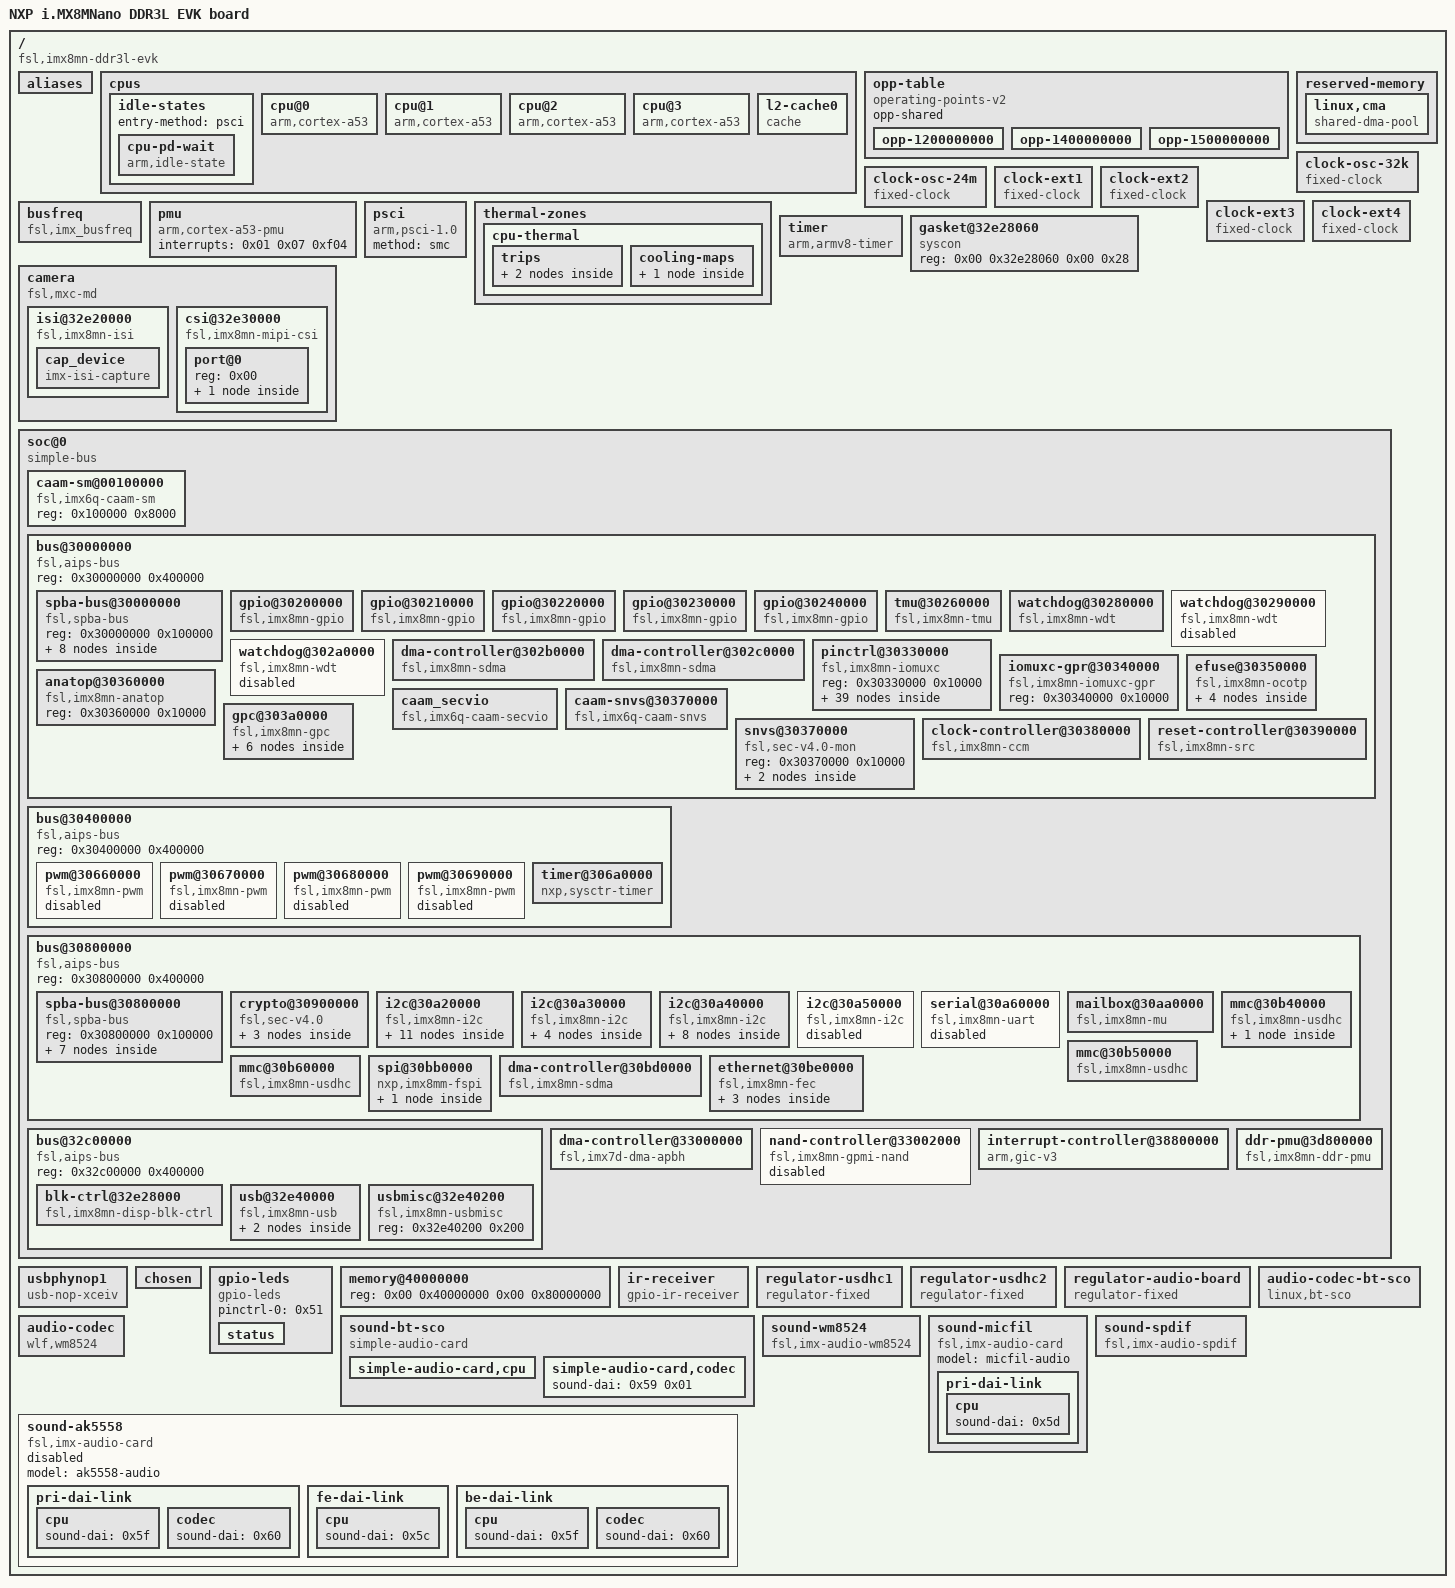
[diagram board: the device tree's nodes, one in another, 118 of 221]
/dts-v1/;

/ {
	interrupt-parent = <0x01>;
	#address-cells = <0x02>;
	#size-cells = <0x02>;
	model = "NXP i.MX8MNano DDR3L EVK board";
	compatible = "fsl,imx8mn-ddr3l-evk\0fsl,imx8mn";

	aliases {
		ethernet0 = "/soc@0/bus@30800000/ethernet@30be0000";
		gpio0 = "/soc@0/bus@30000000/gpio@30200000";
		gpio1 = "/soc@0/bus@30000000/gpio@30210000";
		gpio2 = "/soc@0/bus@30000000/gpio@30220000";
		gpio3 = "/soc@0/bus@30000000/gpio@30230000";
		gpio4 = "/soc@0/bus@30000000/gpio@30240000";
		i2c0 = "/soc@0/bus@30800000/i2c@30a20000";
		i2c1 = "/soc@0/bus@30800000/i2c@30a30000";
		i2c2 = "/soc@0/bus@30800000/i2c@30a40000";
		i2c3 = "/soc@0/bus@30800000/i2c@30a50000";
		mmc0 = "/soc@0/bus@30800000/mmc@30b40000";
		mmc1 = "/soc@0/bus@30800000/mmc@30b50000";
		mmc2 = "/soc@0/bus@30800000/mmc@30b60000";
		serial0 = "/soc@0/bus@30800000/spba-bus@30800000/serial@30860000";
		serial1 = "/soc@0/bus@30800000/spba-bus@30800000/serial@30890000";
		serial2 = "/soc@0/bus@30800000/spba-bus@30800000/serial@30880000";
		serial3 = "/soc@0/bus@30800000/serial@30a60000";
		spi0 = "/soc@0/bus@30800000/spba-bus@30800000/spi@30820000";
		spi1 = "/soc@0/bus@30800000/spba-bus@30800000/spi@30830000";
		spi2 = "/soc@0/bus@30800000/spba-bus@30800000/spi@30840000";
		isi0 = "/camera/isi@32e20000";
		csi0 = "/camera/csi@32e30000";
	};

	cpus {
		#address-cells = <0x01>;
		#size-cells = <0x00>;

		idle-states {
			entry-method = "psci";

			cpu-pd-wait {
				compatible = "arm,idle-state";
				arm,psci-suspend-param = <0x10033>;
				local-timer-stop;
				entry-latency-us = <0x3e8>;
				exit-latency-us = <0x2bc>;
				min-residency-us = <0xa8c>;
				phandle = <0x06>;
			};
		};

		cpu@0 {
			device_type = "cpu";
			compatible = "arm,cortex-a53";
			reg = <0x00>;
			clock-latency = <0xee6c>;
			clocks = <0x02 0xbf>;
			enable-method = "psci";
			i-cache-size = <0x8000>;
			i-cache-line-size = <0x40>;
			i-cache-sets = <0x100>;
			d-cache-size = <0x8000>;
			d-cache-line-size = <0x40>;
			d-cache-sets = <0x80>;
			next-level-cache = <0x03>;
			operating-points-v2 = <0x04>;
			nvmem-cells = <0x05>;
			nvmem-cell-names = "speed_grade";
			cpu-idle-states = <0x06>;
			#cooling-cells = <0x02>;
			cpu-supply = <0x07>;
			phandle = <0x0a>;
		};

		cpu@1 {
			device_type = "cpu";
			compatible = "arm,cortex-a53";
			reg = <0x01>;
			clock-latency = <0xee6c>;
			clocks = <0x02 0xbf>;
			enable-method = "psci";
			i-cache-size = <0x8000>;
			i-cache-line-size = <0x40>;
			i-cache-sets = <0x100>;
			d-cache-size = <0x8000>;
			d-cache-line-size = <0x40>;
			d-cache-sets = <0x80>;
			next-level-cache = <0x03>;
			operating-points-v2 = <0x04>;
			cpu-idle-states = <0x06>;
			#cooling-cells = <0x02>;
			cpu-supply = <0x07>;
			phandle = <0x0b>;
		};

		cpu@2 {
			device_type = "cpu";
			compatible = "arm,cortex-a53";
			reg = <0x02>;
			clock-latency = <0xee6c>;
			clocks = <0x02 0xbf>;
			enable-method = "psci";
			i-cache-size = <0x8000>;
			i-cache-line-size = <0x40>;
			i-cache-sets = <0x100>;
			d-cache-size = <0x8000>;
			d-cache-line-size = <0x40>;
			d-cache-sets = <0x80>;
			next-level-cache = <0x03>;
			operating-points-v2 = <0x04>;
			cpu-idle-states = <0x06>;
			#cooling-cells = <0x02>;
			cpu-supply = <0x07>;
			phandle = <0x0c>;
		};

		cpu@3 {
			device_type = "cpu";
			compatible = "arm,cortex-a53";
			reg = <0x03>;
			clock-latency = <0xee6c>;
			clocks = <0x02 0xbf>;
			enable-method = "psci";
			i-cache-size = <0x8000>;
			i-cache-line-size = <0x40>;
			i-cache-sets = <0x100>;
			d-cache-size = <0x8000>;
			d-cache-line-size = <0x40>;
			d-cache-sets = <0x80>;
			next-level-cache = <0x03>;
			operating-points-v2 = <0x04>;
			cpu-idle-states = <0x06>;
			#cooling-cells = <0x02>;
			cpu-supply = <0x07>;
			phandle = <0x0d>;
		};

		l2-cache0 {
			compatible = "cache";
			cache-level = <0x02>;
			cache-size = <0x80000>;
			cache-line-size = <0x40>;
			cache-sets = <0x200>;
			phandle = <0x03>;
		};
	};

	opp-table {
		compatible = "operating-points-v2";
		opp-shared;
		phandle = <0x04>;

		opp-1200000000 {
			opp-hz = <0x00 0x47868c00>;
			opp-microvolt = <0xcf850>;
			opp-supported-hw = <0xb00 0x07>;
			clock-latency-ns = <0x249f0>;
			opp-suspend;
		};

		opp-1400000000 {
			opp-hz = <0x00 0x53724e00>;
			opp-microvolt = <0xe7ef0>;
			opp-supported-hw = <0x300 0x07>;
			clock-latency-ns = <0x249f0>;
			opp-suspend;
		};

		opp-1500000000 {
			opp-hz = <0x00 0x59682f00>;
			opp-microvolt = <0xf4240>;
			opp-supported-hw = <0x100 0x03>;
			clock-latency-ns = <0x249f0>;
			opp-suspend;
		};
	};

	reserved-memory {
		#address-cells = <0x02>;
		#size-cells = <0x02>;
		ranges;

		linux,cma {
			compatible = "shared-dma-pool";
			reusable;
			size = <0x00 0x28000000>;
			alloc-ranges = <0x00 0x40000000 0x00 0x40000000>;
			linux,cma-default;
		};
	};

	clock-osc-32k {
		compatible = "fixed-clock";
		#clock-cells = <0x00>;
		clock-frequency = <0x8000>;
		clock-output-names = "osc_32k";
		phandle = <0x1b>;
	};

	clock-osc-24m {
		compatible = "fixed-clock";
		#clock-cells = <0x00>;
		clock-frequency = <0x16e3600>;
		clock-output-names = "osc_24m";
		phandle = <0x1c>;
	};

	clock-ext1 {
		compatible = "fixed-clock";
		#clock-cells = <0x00>;
		clock-frequency = <0x7ed6b40>;
		clock-output-names = "clk_ext1";
		phandle = <0x1d>;
	};

	clock-ext2 {
		compatible = "fixed-clock";
		#clock-cells = <0x00>;
		clock-frequency = <0x7ed6b40>;
		clock-output-names = "clk_ext2";
		phandle = <0x1e>;
	};

	clock-ext3 {
		compatible = "fixed-clock";
		#clock-cells = <0x00>;
		clock-frequency = <0x7ed6b40>;
		clock-output-names = "clk_ext3";
		phandle = <0x1f>;
	};

	clock-ext4 {
		compatible = "fixed-clock";
		#clock-cells = <0x00>;
		clock-frequency = <0x7ed6b40>;
		clock-output-names = "clk_ext4";
		phandle = <0x20>;
	};

	busfreq {
		compatible = "fsl,imx_busfreq";
		clocks = <0x02 0x29 0x02 0x59 0x02 0x5a 0x02 0x5a 0x02 0x58 0x02 0x5b 0x02 0x30 0x02 0x32 0x02 0x3f 0x02 0x53 0x02 0x54 0x02 0x4b 0x02 0x02 0x02 0x38 0x02 0x15>;
		clock-names = "dram_pll\0dram_alt_src\0dram_apb_src\0dram_apb_pre_div\0dram_core\0dram_alt_root\0sys_pll1_40m\0sys_pll1_100m\0sys_pll2_333m\0noc_div\0ahb_div\0main_axi_src\0osc_24m\0sys_pll1_800m\0dram_pll_div";
	};

	pmu {
		compatible = "arm,cortex-a53-pmu";
		interrupts = <0x01 0x07 0xf04>;
	};

	psci {
		compatible = "arm,psci-1.0";
		method = "smc";
	};

	thermal-zones {

		cpu-thermal {
			polling-delay-passive = <0xfa>;
			polling-delay = <0x7d0>;
			thermal-sensors = <0x08>;

			trips {

				trip0 {
					temperature = <0x14c08>;
					hysteresis = <0x7d0>;
					type = "passive";
					phandle = <0x09>;
				};

				trip1 {
					temperature = <0x17318>;
					hysteresis = <0x7d0>;
					type = "critical";
				};
			};

			cooling-maps {

				map0 {
					trip = <0x09>;
					cooling-device = <0x0a 0xffffffff 0xffffffff 0x0b 0xffffffff 0xffffffff 0x0c 0xffffffff 0xffffffff 0x0d 0xffffffff 0xffffffff>;
				};
			};
		};
	};

	timer {
		compatible = "arm,armv8-timer";
		interrupts = <0x01 0x0d 0xf08 0x01 0x0e 0xf08 0x01 0x0b 0xf08 0x01 0x0a 0xf08>;
		clock-frequency = <0x7a1200>;
		arm,no-tick-in-suspend;
	};

	gasket@32e28060 {
		compatible = "syscon";
		reg = <0x00 0x32e28060 0x00 0x28>;
		phandle = <0x0f>;
	};

	camera {
		compatible = "fsl,mxc-md\0simple-bus";
		#address-cells = <0x02>;
		#size-cells = <0x02>;
		ranges;
		status = "okay";

		isi@32e20000 {
			compatible = "fsl,imx8mn-isi";
			reg = <0x00 0x32e20000 0x00 0x2000>;
			power-domains = <0x0e 0x03>;
			interrupts = <0x00 0x10 0x04>;
			interface = <0x02 0x00 0x02>;
			clocks = <0x02 0x4e 0x02 0x4f 0x02 0xb8 0x02 0xb9>;
			clock-names = "disp_axi\0disp_apb\0disp_axi_root\0disp_apb_root";
			assigned-clocks = <0x02 0xb8 0x02 0xb9>;
			assigned-clock-rates = <0x1dcd6500 0xbebc200>;
			no-reset-control;
			status = "okay";

			cap_device {
				compatible = "imx-isi-capture";
				status = "okay";
			};
		};

		csi@32e30000 {
			compatible = "fsl,imx8mn-mipi-csi";
			reg = <0x00 0x32e30000 0x00 0x10000>;
			interrupts = <0x00 0x11 0x04>;
			clock-frequency = <0x13d92d40>;
			clocks = <0x02 0x81 0x02 0xb8 0x02 0xb9>;
			clock-names = "mipi_clk\0disp_axi\0disp_apb";
			assigned-clocks = <0x02 0x81>;
			assigned-clock-parents = <0x02 0x41>;
			assigned-clock-rates = <0x13d92d40>;
			bus-width = <0x04>;
			csi-gpr = <0x0f>;
			power-domains = <0x0e 0x01>;
			status = "okay";
			#address-cells = <0x01>;
			#size-cells = <0x00>;

			port@0 {
				reg = <0x00>;

				endpoint {
					remote-endpoint = <0x10>;
					data-lanes = <0x02>;
					csis-hs-settle = <0x0d>;
					csis-clk-settle = <0x02>;
					csis-wclk;
					phandle = <0x35>;
				};
			};
		};
	};

	soc@0 {
		compatible = "simple-bus";
		#address-cells = <0x01>;
		#size-cells = <0x01>;
		ranges = <0x00 0x00 0x00 0x3e000000>;
		dma-ranges = <0x40000000 0x00 0x40000000 0xc0000000>;
		nvmem-cells = <0x11>;
		nvmem-cell-names = "soc_unique_id";

		caam-sm@00100000 {
			compatible = "fsl,imx6q-caam-sm";
			reg = <0x100000 0x8000>;
		};

		bus@30000000 {
			compatible = "fsl,aips-bus\0simple-bus";
			reg = <0x30000000 0x400000>;
			#address-cells = <0x01>;
			#size-cells = <0x01>;
			ranges;

			spba-bus@30000000 {
				compatible = "fsl,spba-bus\0simple-bus";
				#address-cells = <0x01>;
				#size-cells = <0x01>;
				reg = <0x30000000 0x100000>;
				ranges;

				sai@30020000 {
					compatible = "fsl,imx8mn-sai\0fsl,imx8mq-sai";
					reg = <0x30020000 0x10000>;
					#sound-dai-cells = <0x00>;
					interrupts = <0x00 0x60 0x04>;
					clocks = <0x02 0x9e 0x02 0x00 0x02 0x9d 0x02 0x00 0x02 0x00>;
					clock-names = "bus\0mclk0\0mclk1\0mclk2\0mclk3";
					dmas = <0x12 0x02 0x02 0x00 0x12 0x03 0x02 0x00>;
					dma-names = "rx\0tx";
					status = "okay";
					pinctrl-names = "default";
					pinctrl-0 = <0x13>;
					assigned-clocks = <0x02 0x5d>;
					assigned-clock-parents = <0x02 0x26>;
					assigned-clock-rates = <0x1770000>;
					fsl,sai-mclk-direction-output;
					phandle = <0x58>;
				};

				sai@30030000 {
					compatible = "fsl,imx8mn-sai\0fsl,imx8mq-sai";
					reg = <0x30030000 0x10000>;
					#sound-dai-cells = <0x00>;
					interrupts = <0x00 0x32 0x04>;
					clocks = <0x02 0xa0 0x02 0x00 0x02 0x9f 0x02 0x00 0x02 0x00>;
					clock-names = "bus\0mclk0\0mclk1\0mclk2\0mclk3";
					dmas = <0x12 0x04 0x02 0x00 0x12 0x05 0x02 0x00>;
					dma-names = "rx\0tx";
					status = "okay";
					pinctrl-names = "default";
					pinctrl-0 = <0x14>;
					assigned-clocks = <0x02 0x5e>;
					assigned-clock-parents = <0x02 0x26>;
					assigned-clock-rates = <0x1770000>;
					fsl,sai-mclk-direction-output;
					phandle = <0x5a>;
				};

				sai@30050000 {
					compatible = "fsl,imx8mn-sai\0fsl,imx8mq-sai";
					reg = <0x30050000 0x10000>;
					#sound-dai-cells = <0x00>;
					interrupts = <0x00 0x5a 0x04>;
					clocks = <0x02 0xa2 0x02 0x00 0x02 0xa1 0x02 0x00 0x02 0x00 0x02 0x26 0x02 0x27>;
					clock-names = "bus\0mclk0\0mclk1\0mclk2\0mclk3\0pll8k\0pll11k";
					dmas = <0x12 0x08 0x19 0x00 0x12 0x09 0x19 0x00>;
					dma-names = "rx\0tx";
					fsl,shared-interrupt;
					fsl,dataline = <0x00 0x0f 0x0f>;
					status = "disabled";
					pinctrl-names = "default";
					pinctrl-0 = <0x15>;
					assigned-clocks = <0x02 0x5f>;
					assigned-clock-parents = <0x02 0x26>;
					assigned-clock-rates = <0x2ee0000>;
					fsl,sai-asynchronous;
					fsl,sai-multi-lane;
					fsl,sai-mclk-direction-output;
					phandle = <0x5f>;
				};

				sai@30060000 {
					compatible = "fsl,imx8mn-sai\0fsl,imx8mq-sai";
					reg = <0x30060000 0x10000>;
					#sound-dai-cells = <0x00>;
					interrupts = <0x00 0x5a 0x04>;
					clocks = <0x02 0xa4 0x02 0x00 0x02 0xa3 0x02 0x00 0x02 0x00>;
					clock-names = "bus\0mclk0\0mclk1\0mclk2\0mclk3";
					dmas = <0x12 0x0a 0x02 0x00 0x12 0x0b 0x02 0x00>;
					dma-names = "rx\0tx";
					status = "disabled";
				};

				audio-controller@30080000 {
					compatible = "fsl,imx8mm-micfil";
					reg = <0x30080000 0x10000>;
					interrupts = <0x00 0x6d 0x04 0x00 0x6e 0x04 0x00 0x2c 0x04 0x00 0x2d 0x04>;
					clocks = <0x02 0xb7 0x02 0xb6 0x02 0x26 0x02 0x27 0x02 0x06>;
					clock-names = "ipg_clk\0ipg_clk_app\0pll8k\0pll11k\0clkext3";
					dmas = <0x12 0x18 0x19 0x80000000>;
					dma-names = "rx";
					status = "okay";
					#sound-dai-cells = <0x00>;
					pinctrl-names = "default";
					pinctrl-0 = <0x16>;
					assigned-clocks = <0x02 0x86>;
					assigned-clock-parents = <0x02 0x26>;
					assigned-clock-rates = <0xbb80000>;
					phandle = <0x5d>;
				};

				spdif@30090000 {
					compatible = "fsl,imx35-spdif";
					reg = <0x30090000 0x10000>;
					interrupts = <0x00 0x06 0x04>;
					clocks = <0x02 0x55 0x02 0x02 0x02 0x61 0x02 0x00 0x02 0x00 0x02 0x00 0x02 0x55 0x02 0x00 0x02 0x00 0x02 0x00 0x02 0x26 0x02 0x27>;
					clock-names = "core\0rxtx0\0rxtx1\0rxtx2\0rxtx3\0rxtx4\0rxtx5\0rxtx6\0rxtx7\0spba\0pll8k\0pll11k";
					dmas = <0x12 0x1c 0x12 0x00 0x12 0x1d 0x12 0x00>;
					dma-names = "rx\0tx";
					status = "okay";
					pinctrl-names = "default";
					pinctrl-0 = <0x17>;
					assigned-clocks = <0x02 0x61>;
					assigned-clock-parents = <0x02 0x26>;
					assigned-clock-rates = <0x1770000>;
					phandle = <0x5e>;
				};

				sai@300b0000 {
					compatible = "fsl,imx8mn-sai\0fsl,imx8mq-sai";
					reg = <0x300b0000 0x10000>;
					#sound-dai-cells = <0x00>;
					interrupts = <0x00 0x6f 0x04>;
					clocks = <0x02 0xa6 0x02 0x00 0x02 0xa5 0x02 0x00 0x02 0x00>;
					clock-names = "bus\0mclk0\0mclk1\0mclk2\0mclk3";
					dmas = <0x12 0x0c 0x02 0x00 0x12 0x0d 0x02 0x00>;
					dma-names = "rx\0tx";
					status = "disabled";
				};

				easrc@300c0000 {
					compatible = "fsl,imx8mn-easrc";
					reg = <0x300c0000 0x10000>;
					interrupts = <0x00 0x7a 0x04>;
					clocks = <0x02 0xb4>;
					clock-names = "mem";
					dmas = <0x12 0x10 0x17 0x00 0x12 0x11 0x17 0x00 0x12 0x12 0x17 0x00 0x12 0x13 0x17 0x00 0x12 0x14 0x17 0x00 0x12 0x15 0x17 0x00 0x12 0x16 0x17 0x00 0x12 0x17 0x17 0x00>;
					dma-names = "ctx0_rx\0ctx0_tx\0ctx1_rx\0ctx1_tx\0ctx2_rx\0ctx2_tx\0ctx3_rx\0ctx3_tx";
					firmware-name = "imx/easrc/easrc-imx8mn.bin";
					fsl,asrc-rate = <0xbb80>;
					fsl,asrc-format = <0x02>;
					status = "okay";
					#sound-dai-cells = <0x00>;
					phandle = <0x5c>;
				};
			};

			gpio@30200000 {
				compatible = "fsl,imx8mn-gpio\0fsl,imx35-gpio";
				reg = <0x30200000 0x10000>;
				interrupts = <0x00 0x40 0x04 0x00 0x41 0x04>;
				clocks = <0x02 0x8c>;
				gpio-controller;
				#gpio-cells = <0x02>;
				interrupt-controller;
				#interrupt-cells = <0x02>;
				gpio-ranges = <0x18 0x00 0x0a 0x1e>;
				phandle = <0x28>;
			};

			gpio@30210000 {
				compatible = "fsl,imx8mn-gpio\0fsl,imx35-gpio";
				reg = <0x30210000 0x10000>;
				interrupts = <0x00 0x42 0x04 0x00 0x43 0x04>;
				clocks = <0x02 0x8d>;
				gpio-controller;
				#gpio-cells = <0x02>;
				interrupt-controller;
				#interrupt-cells = <0x02>;
				gpio-ranges = <0x18 0x00 0x28 0x15>;
				phandle = <0x2d>;
			};

			gpio@30220000 {
				compatible = "fsl,imx8mn-gpio\0fsl,imx35-gpio";
				reg = <0x30220000 0x10000>;
				interrupts = <0x00 0x44 0x04 0x00 0x45 0x04>;
				clocks = <0x02 0x8e>;
				gpio-controller;
				#gpio-cells = <0x02>;
				interrupt-controller;
				#interrupt-cells = <0x02>;
				gpio-ranges = <0x18 0x00 0x3d 0x1a>;
				phandle = <0x52>;
			};

			gpio@30230000 {
				compatible = "fsl,imx8mn-gpio\0fsl,imx35-gpio";
				reg = <0x30230000 0x10000>;
				interrupts = <0x00 0x46 0x04 0x00 0x47 0x04>;
				clocks = <0x02 0x8f>;
				gpio-controller;
				#gpio-cells = <0x02>;
				interrupt-controller;
				#interrupt-cells = <0x02>;
				gpio-ranges = <0x18 0x15 0x6c 0x0b>;
				phandle = <0x48>;
			};

			gpio@30240000 {
				compatible = "fsl,imx8mn-gpio\0fsl,imx35-gpio";
				reg = <0x30240000 0x10000>;
				interrupts = <0x00 0x48 0x04 0x00 0x49 0x04>;
				clocks = <0x02 0x90>;
				gpio-controller;
				#gpio-cells = <0x02>;
				interrupt-controller;
				#interrupt-cells = <0x02>;
				gpio-ranges = <0x18 0x00 0x77 0x1e>;
				phandle = <0x2b>;
			};

			tmu@30260000 {
				compatible = "fsl,imx8mn-tmu\0fsl,imx8mm-tmu";
				reg = <0x30260000 0x10000>;
				clocks = <0x02 0xbe>;
				#thermal-sensor-cells = <0x00>;
				phandle = <0x08>;
			};

			watchdog@30280000 {
				compatible = "fsl,imx8mn-wdt\0fsl,imx21-wdt";
				reg = <0x30280000 0x10000>;
				interrupts = <0x00 0x4e 0x04>;
				clocks = <0x02 0xb0>;
				status = "okay";
				pinctrl-names = "default";
				pinctrl-0 = <0x19>;
				fsl,ext-reset-output;
			};

			watchdog@30290000 {
				compatible = "fsl,imx8mn-wdt\0fsl,imx21-wdt";
				reg = <0x30290000 0x10000>;
				interrupts = <0x00 0x4f 0x04>;
				clocks = <0x02 0xb1>;
				status = "disabled";
			};

			watchdog@302a0000 {
				compatible = "fsl,imx8mn-wdt\0fsl,imx21-wdt";
				reg = <0x302a0000 0x10000>;
				interrupts = <0x00 0x0a 0x04>;
				clocks = <0x02 0xb2>;
				status = "disabled";
			};

			dma-controller@302b0000 {
				compatible = "fsl,imx8mn-sdma\0fsl,imx8mq-sdma\0fsl,imx7d-sdma";
				reg = <0x302b0000 0x10000>;
				interrupts = <0x00 0x22 0x04>;
				clocks = <0x02 0xbd 0x02 0xbd>;
				clock-names = "ipg\0ahb";
				#dma-cells = <0x03>;
				fsl,sdma-ram-script-name = "imx/sdma/sdma-imx7d.bin";
			};

			dma-controller@302c0000 {
				compatible = "fsl,imx8mn-sdma\0fsl,imx8mq-sdma\0fsl,imx7d-sdma";
				reg = <0x302c0000 0x10000>;
				interrupts = <0x00 0x67 0x04>;
				clocks = <0x02 0xa8 0x02 0xa8>;
				clock-names = "ipg\0ahb";
				#dma-cells = <0x03>;
				fsl,sdma-ram-script-name = "imx/sdma/sdma-imx7d.bin";
				phandle = <0x12>;
			};

			pinctrl@30330000 {
				compatible = "fsl,imx8mn-iomuxc";
				reg = <0x30330000 0x10000>;
				phandle = <0x18>;

				csi_pwn_grp {
					fsl,pins = <0x44 0x2ac 0x00 0x00 0x00 0x19>;
					phandle = <0x33>;
				};

				csi_rst_grp {
					fsl,pins = <0x40 0x2a8 0x00 0x00 0x00 0x19 0x60 0x2c8 0x00 0x06 0x00 0x59>;
					phandle = <0x34>;
				};

				ir-recv {
					fsl,pins = <0x5c 0x2c4 0x00 0x00 0x00 0x4f>;
				};

				fec1grp {
					fsl,pins = <0x68 0x2d0 0x00 0x00 0x00 0x03 0x6c 0x2d4 0x4c0 0x00 0x01 0x03 0x70 0x2d8 0x00 0x00 0x00 0x1f 0x74 0x2dc 0x00 0x00 0x00 0x1f 0x78 0x2e0 0x00 0x00 0x00 0x1f 0x7c 0x2e4 0x00 0x00 0x00 0x1f 0x9c 0x304 0x00 0x00 0x00 0x91 0x98 0x300 0x00 0x00 0x00 0x91 0x94 0x2fc 0x554 0x00 0x00 0x91 0x90 0x2f8 0x57c 0x00 0x00 0x91 0x84 0x2ec 0x00 0x00 0x00 0x1f 0x8c 0x2f4 0x00 0x00 0x00 0x91 0x88 0x2f0 0x574 0x00 0x00 0x91 0x80 0x2e8 0x00 0x00 0x00 0x1f 0x1b4 0x41c 0x00 0x05 0x00 0x19>;
					phandle = <0x46>;
				};

				flexspigrp {
					fsl,pins = <0xf4 0x35c 0x00 0x01 0x00 0x1c2 0xf8 0x360 0x00 0x01 0x00 0x82 0x10c 0x374 0x00 0x01 0x00 0x82 0x110 0x378 0x00 0x01 0x00 0x82 0x114 0x37c 0x00 0x01 0x00 0x82 0x118 0x380 0x00 0x01 0x00 0x82>;
					phandle = <0x43>;
				};

				gpioledgrp {
					fsl,pins = <0x134 0x39c 0x00 0x05 0x00 0x19>;
					phandle = <0x51>;
				};

				i2c2grp-gpio {
					fsl,pins = <0x21c 0x484 0x00 0x05 0x00 0x1c3 0x220 0x488 0x00 0x05 0x00 0x1c3>;
					phandle = <0x2a>;
				};

				synaptics_dsx_iogrp {
					fsl,pins = <0x4c 0x2b4 0x00 0x00 0x00 0x19>;
				};

				gpiowlfgrp {
					fsl,pins = <0x230 0x498 0x00 0x05 0x00 0xd6>;
					phandle = <0x56>;
				};

				irgrp {
					fsl,pins = <0x5c 0x2c4 0x00 0x00 0x00 0x4f>;
					phandle = <0x53>;
				};

				i2c1grp {
					fsl,pins = <0x214 0x47c 0x55c 0x00 0x00 0x400001c3 0x218 0x480 0x56c 0x00 0x00 0x400001c3>;
					phandle = <0x26>;
				};

				i2c2grp {
					fsl,pins = <0x21c 0x484 0x5d0 0x00 0x00 0x400001c3 0x220 0x488 0x560 0x00 0x00 0x400001c3>;
					phandle = <0x29>;
				};

				i2c3grp {
					fsl,pins = <0x224 0x48c 0x588 0x00 0x00 0x400001c3 0x228 0x490 0x5bc 0x00 0x00 0x400001c3>;
					phandle = <0x2f>;
				};

				i2c3grp-gpio {
					fsl,pins = <0x224 0x48c 0x00 0x05 0x00 0x1c3 0x228 0x490 0x00 0x05 0x00 0x1c3>;
					phandle = <0x30>;
				};

				pmicirqgrp {
					fsl,pins = <0x34 0x29c 0x00 0x00 0x00 0x141>;
					phandle = <0x27>;
				};

				mipi_dsi_en {
					fsl,pins = <0x48 0x2b0 0x00 0x00 0x00 0x16>;
				};

				pdmgrp {
					fsl,pins = <0x158 0x3c0 0x594 0x00 0x00 0xd6 0x144 0x3ac 0x00 0x04 0x00 0xd6 0x140 0x3a8 0x4e4 0x00 0x00 0xd6 0x148 0x3b0 0x534 0x04 0x00 0xd6 0x14c 0x3b4 0x538 0x04 0x00 0xd6 0x150 0x3b8 0x53c 0x04 0x00 0xd6 0x154 0x3bc 0x540 0x04 0x00 0xd6>;
					phandle = <0x16>;
				};

				sai5grp {
					fsl,pins = <0x158 0x3c0 0x594 0x00 0x00 0xd6 0x144 0x3ac 0x4d0 0x00 0x00 0xd6 0x140 0x3a8 0x4e4 0x00 0x00 0xd6 0x148 0x3b0 0x4d4 0x00 0x00 0xd6 0x14c 0x3b4 0x4d8 0x00 0x00 0xd6 0x150 0x3b8 0x4dc 0x00 0x00 0xd6 0x154 0x3bc 0x4e0 0x00 0x00 0xd6>;
					phandle = <0x15>;
				};

				regusdhc2vmmcgrp {
					fsl,pins = <0xec 0x354 0x00 0x05 0x00 0x41>;
					phandle = <0x55>;
				};

				sai2grp {
					fsl,pins = <0x1c0 0x428 0x00 0x00 0x00 0xd6 0x1bc 0x424 0x00 0x00 0x00 0xd6 0x1c4 0x42c 0x00 0x00 0x00 0xd6 0x1b8 0x420 0x00 0x00 0x00 0xd6>;
					phandle = <0x13>;
				};

				sai3grp {
					fsl,pins = <0x1d8 0x440 0x00 0x00 0x00 0xd6 0x1dc 0x444 0x00 0x00 0x00 0xd6 0x1e4 0x44c 0x5c0 0x00 0x00 0xd6 0x1e0 0x448 0x00 0x00 0x00 0xd6>;
					phandle = <0x14>;
				};

				spdif1grp {
					fsl,pins = <0x1e8 0x450 0x00 0x00 0x00 0xd6 0x1ec 0x454 0x5cc 0x00 0x00 0xd6>;
					phandle = <0x17>;
				};

				typec1grp {
					fsl,pins = <0xcc 0x334 0x00 0x05 0x00 0x159>;
					phandle = <0x2c>;
				};

				uart1grp {
					fsl,pins = <0x234 0x49c 0x4f4 0x00 0x00 0x140 0x238 0x4a0 0x00 0x00 0x00 0x140 0x244 0x4ac 0x00 0x01 0x00 0x140 0x248 0x4b0 0x4f0 0x01 0x01 0x140>;
					phandle = <0x23>;
				};

				uart2grp {
					fsl,pins = <0x23c 0x4a4 0x4fc 0x00 0x00 0x140 0x240 0x4a8 0x00 0x00 0x00 0x140>;
					phandle = <0x25>;
				};

				uart3grp {
					fsl,pins = <0x1f4 0x45c 0x504 0x01 0x00 0x140 0x1f8 0x460 0x00 0x01 0x00 0x140 0x200 0x468 0x500 0x01 0x01 0x140 0x1fc 0x464 0x00 0x01 0x00 0x140>;
					phandle = <0x24>;
				};

				regusdhc1vmmcgrp {
					fsl,pins = <0xc8 0x330 0x00 0x05 0x00 0x141>;
					phandle = <0x54>;
				};

				usdhc1grp {
					fsl,pins = <0xa0 0x308 0x00 0x00 0x00 0x190 0xa4 0x30c 0x00 0x00 0x00 0x1d0 0xa8 0x310 0x00 0x00 0x00 0x1d0 0xac 0x314 0x00 0x00 0x00 0x1d0 0xb0 0x318 0x00 0x00 0x00 0x1d0 0xb4 0x31c 0x00 0x00 0x00 0x1d0>;
					phandle = <0x36>;
				};

				usdhc1grp100mhz {
					fsl,pins = <0xa0 0x308 0x00 0x00 0x00 0x194 0xa4 0x30c 0x00 0x00 0x00 0x1d4 0xa8 0x310 0x00 0x00 0x00 0x1d4 0xac 0x314 0x00 0x00 0x00 0x1d4 0xb0 0x318 0x00 0x00 0x00 0x1d4 0xb4 0x31c 0x00 0x00 0x00 0x1d4>;
					phandle = <0x38>;
				};

				usdhc1grp200mhz {
					fsl,pins = <0xa0 0x308 0x00 0x00 0x00 0x196 0xa4 0x30c 0x00 0x00 0x00 0x1d6 0xa8 0x310 0x00 0x00 0x00 0x1d6 0xac 0x314 0x00 0x00 0x00 0x1d6 0xb0 0x318 0x00 0x00 0x00 0x1d6 0xb4 0x31c 0x00 0x00 0x00 0x1d6>;
					phandle = <0x39>;
				};

				usdhc2gpiogrp {
					fsl,pins = <0x64 0x2cc 0x00 0x00 0x00 0x1c4>;
					phandle = <0x3c>;
				};

				usdhc2grp {
					fsl,pins = <0xd4 0x33c 0x00 0x00 0x00 0x190 0xd8 0x340 0x00 0x00 0x00 0x1d0 0xdc 0x344 0x00 0x00 0x00 0x1d0 0xe0 0x348 0x00 0x00 0x00 0x1d0 0xe4 0x34c 0x00 0x00 0x00 0x1d0 0xe8 0x350 0x00 0x00 0x00 0x1d0 0x38 0x2a0 0x00 0x01 0x00 0x1d0>;
					phandle = <0x3b>;
				};

				usdhc2-100mhzgrp {
					fsl,pins = <0xd4 0x33c 0x00 0x00 0x00 0x194 0xd8 0x340 0x00 0x00 0x00 0x1d4 0xdc 0x344 0x00 0x00 0x00 0x1d4 0xe0 0x348 0x00 0x00 0x00 0x1d4 0xe4 0x34c 0x00 0x00 0x00 0x1d4 0xe8 0x350 0x00 0x00 0x00 0x1d4 0x38 0x2a0 0x00 0x01 0x00 0x1d0>;
					phandle = <0x3d>;
				};

				usdhc2-200mhzgrp {
					fsl,pins = <0xd4 0x33c 0x00 0x00 0x00 0x196 0xd8 0x340 0x00 0x00 0x00 0x1d6 0xdc 0x344 0x00 0x00 0x00 0x1d6 0xe0 0x348 0x00 0x00 0x00 0x1d6 0xe4 0x34c 0x00 0x00 0x00 0x1d6 0xe8 0x350 0x00 0x00 0x00 0x1d6 0x38 0x2a0 0x00 0x01 0x00 0x1d0>;
					phandle = <0x3e>;
				};

				usdhc3grp {
					fsl,pins = <0x138 0x3a0 0x5a0 0x02 0x00 0x40000190 0x13c 0x3a4 0x5dc 0x02 0x00 0x1d0 0x11c 0x384 0x5b4 0x02 0x00 0x1d0 0x120 0x388 0x5b0 0x02 0x00 0x1d0 0x124 0x38c 0x5e4 0x02 0x00 0x1d0 0x128 0x390 0x5e0 0x02 0x00 0x1d0 0x130 0x398 0x558 0x02 0x00 0x1d0 0x100 0x368 0x550 0x02 0x00 0x1d0 0x104 0x36c 0x584 0x02 0x00 0x1d0 0x108 0x370 0x54c 0x02 0x00 0x1d0 0xfc 0x364 0x59c 0x02 0x00 0x190>;
					phandle = <0x40>;
				};

				usdhc3-100mhzgrp {
					fsl,pins = <0x138 0x3a0 0x5a0 0x02 0x00 0x40000194 0x13c 0x3a4 0x5dc 0x02 0x00 0x1d4 0x11c 0x384 0x5b4 0x02 0x00 0x1d4 0x120 0x388 0x5b0 0x02 0x00 0x1d4 0x124 0x38c 0x5e4 0x02 0x00 0x1d4 0x128 0x390 0x5e0 0x02 0x00 0x1d4 0x130 0x398 0x558 0x02 0x00 0x1d4 0x100 0x368 0x550 0x02 0x00 0x1d4 0x104 0x36c 0x584 0x02 0x00 0x1d4 0x108 0x370 0x54c 0x02 0x00 0x1d4 0xfc 0x364 0x59c 0x02 0x00 0x194>;
					phandle = <0x41>;
				};

				usdhc3-200mhzgrp {
					fsl,pins = <0x138 0x3a0 0x5a0 0x02 0x00 0x40000196 0x13c 0x3a4 0x5dc 0x02 0x00 0x1d6 0x11c 0x384 0x5b4 0x02 0x00 0x1d6 0x120 0x388 0x5b0 0x02 0x00 0x1d6 0x124 0x38c 0x5e4 0x02 0x00 0x1d6 0x128 0x390 0x5e0 0x02 0x00 0x1d6 0x130 0x398 0x558 0x02 0x00 0x1d6 0x100 0x368 0x550 0x02 0x00 0x1d6 0x104 0x36c 0x584 0x02 0x00 0x1d6 0x108 0x370 0x54c 0x02 0x00 0x1d6 0xfc 0x364 0x59c 0x02 0x00 0x196>;
					phandle = <0x42>;
				};

				wdoggrp {
					fsl,pins = <0x30 0x298 0x00 0x01 0x00 0x166>;
					phandle = <0x19>;
				};

				wlangrp {
					fsl,pins = <0x28 0x290 0x00 0x05 0x00 0x141 0xc4 0x32c 0x00 0x05 0x00 0x159>;
					phandle = <0x37>;
				};
			};

			iomuxc-gpr@30340000 {
				compatible = "fsl,imx8mn-iomuxc-gpr\0syscon";
				reg = <0x30340000 0x10000>;
				phandle = <0x45>;
			};

			efuse@30350000 {
				compatible = "fsl,imx8mn-ocotp\0fsl,imx8mm-ocotp\0syscon\0simple-mfd";
				reg = <0x30350000 0x10000>;
				clocks = <0x02 0x96>;
				#address-cells = <0x01>;
				#size-cells = <0x01>;

				unique-id@4 {
					reg = <0x04 0x08>;
					phandle = <0x11>;
				};

				speed-grade@10 {
					reg = <0x10 0x04>;
					phandle = <0x05>;
				};

				mac-address@90 {
					reg = <0x90 0x06>;
					phandle = <0x44>;
				};

				imx8mn-soc {
					compatible = "fsl,imx8mn-soc";
					nvmem-cells = <0x11>;
					nvmem-cell-names = "soc_unique_id";
				};
			};

			anatop@30360000 {
				compatible = "fsl,imx8mn-anatop\0fsl,imx8mm-anatop\0syscon";
				reg = <0x30360000 0x10000>;
			};

			caam_secvio {
				compatible = "fsl,imx6q-caam-secvio";
				interrupts = <0x00 0x14 0x04>;
				jtag-tamper = "disabled";
				watchdog-tamper = "enabled";
				internal-boot-tamper = "enabled";
				external-pin-tamper = "disabled";
			};

			caam-snvs@30370000 {
				compatible = "fsl,imx6q-caam-snvs";
				reg = <0x30370000 0x10000>;
				clocks = <0x02 0xd3>;
				clock-names = "ipg";
			};

			snvs@30370000 {
				compatible = "fsl,sec-v4.0-mon\0syscon\0simple-mfd";
				reg = <0x30370000 0x10000>;
				phandle = <0x1a>;

				snvs-rtc-lp {
					compatible = "fsl,sec-v4.0-mon-rtc-lp";
					regmap = <0x1a>;
					offset = <0x34>;
					interrupts = <0x00 0x13 0x04 0x00 0x14 0x04>;
					clocks = <0x02 0xd3>;
					clock-names = "snvs-rtc";
				};

				snvs-powerkey {
					compatible = "fsl,sec-v4.0-pwrkey";
					regmap = <0x1a>;
					interrupts = <0x00 0x04 0x04>;
					clocks = <0x02 0xd3>;
					clock-names = "snvs-pwrkey";
					linux,keycode = <0x74>;
					wakeup-source;
					status = "okay";
				};
			};

			clock-controller@30380000 {
				compatible = "fsl,imx8mn-ccm";
				reg = <0x30380000 0x10000>;
				#clock-cells = <0x01>;
				clocks = <0x1b 0x1c 0x1d 0x1e 0x1f 0x20>;
				clock-names = "osc_32k\0osc_24m\0clk_ext1\0clk_ext2\0clk_ext3\0clk_ext4";
				assigned-clocks = <0x02 0x42 0x02 0xd6 0x02 0x53 0x02 0x55 0x02 0x57 0x02 0x1b 0x02 0x14 0x02 0x12 0x02 0x13>;
				assigned-clock-parents = <0x02 0x38 0x02 0x2c 0x02 0x2f 0x02 0x38>;
				assigned-clock-rates = <0x00 0x00 0x00 0x17d78400 0x17d78400 0x23c34600 0x3df582e0 0x17700000 0x15888000>;
				phandle = <0x02>;
			};

			reset-controller@30390000 {
				compatible = "fsl,imx8mn-src\0fsl,imx8mq-src\0syscon";
				reg = <0x30390000 0x10000>;
				interrupts = <0x00 0x59 0x04>;
				#reset-cells = <0x01>;
			};

			gpc@303a0000 {
				compatible = "fsl,imx8mn-gpc";
				reg = <0x303a0000 0x10000>;
				interrupt-parent = <0x01>;
				interrupts = <0x00 0x57 0x04>;

				pgc {
					#address-cells = <0x01>;
					#size-cells = <0x00>;

					power-domain@0 {
						#power-domain-cells = <0x00>;
						reg = <0x00>;
						clocks = <0x02 0x50>;
						phandle = <0x4d>;
					};

					power-domain@1 {
						#power-domain-cells = <0x00>;
						reg = <0x01>;
						phandle = <0x50>;
					};

					power-domain@2 {
						#power-domain-cells = <0x00>;
						reg = <0x02>;
						clocks = <0x02 0xc1 0x02 0xd5 0x02 0xb3 0x02 0x52>;
					};

					power-domain@3 {
						#power-domain-cells = <0x00>;
						reg = <0x03>;
						clocks = <0x02 0xb8 0x02 0xb9>;
						phandle = <0x21>;
					};

					power-domain@4 {
						#power-domain-cells = <0x00>;
						reg = <0x04>;
						power-domains = <0x21>;
						phandle = <0x4a>;
					};
				};
			};
		};

		bus@30400000 {
			compatible = "fsl,aips-bus\0simple-bus";
			reg = <0x30400000 0x400000>;
			#address-cells = <0x01>;
			#size-cells = <0x01>;
			ranges;

			pwm@30660000 {
				compatible = "fsl,imx8mn-pwm\0fsl,imx27-pwm";
				reg = <0x30660000 0x10000>;
				interrupts = <0x00 0x51 0x04>;
				clocks = <0x02 0x97 0x02 0x97>;
				clock-names = "ipg\0per";
				#pwm-cells = <0x03>;
				status = "disabled";
			};

			pwm@30670000 {
				compatible = "fsl,imx8mn-pwm\0fsl,imx27-pwm";
				reg = <0x30670000 0x10000>;
				interrupts = <0x00 0x52 0x04>;
				clocks = <0x02 0x98 0x02 0x98>;
				clock-names = "ipg\0per";
				#pwm-cells = <0x03>;
				status = "disabled";
			};

			pwm@30680000 {
				compatible = "fsl,imx8mn-pwm\0fsl,imx27-pwm";
				reg = <0x30680000 0x10000>;
				interrupts = <0x00 0x53 0x04>;
				clocks = <0x02 0x99 0x02 0x99>;
				clock-names = "ipg\0per";
				#pwm-cells = <0x03>;
				status = "disabled";
			};

			pwm@30690000 {
				compatible = "fsl,imx8mn-pwm\0fsl,imx27-pwm";
				reg = <0x30690000 0x10000>;
				interrupts = <0x00 0x54 0x04>;
				clocks = <0x02 0x9a 0x02 0x9a>;
				clock-names = "ipg\0per";
				#pwm-cells = <0x03>;
				status = "disabled";
			};

			timer@306a0000 {
				compatible = "nxp,sysctr-timer";
				reg = <0x306a0000 0x20000>;
				interrupts = <0x00 0x2f 0x04>;
				clocks = <0x1c>;
				clock-names = "per";
			};
		};

		bus@30800000 {
			compatible = "fsl,aips-bus\0simple-bus";
			reg = <0x30800000 0x400000>;
			#address-cells = <0x01>;
			#size-cells = <0x01>;
			ranges;

			spba-bus@30800000 {
				compatible = "fsl,spba-bus\0simple-bus";
				#address-cells = <0x01>;
				#size-cells = <0x01>;
				reg = <0x30800000 0x100000>;
				ranges;

				spi@30820000 {
					compatible = "fsl,imx8mn-ecspi\0fsl,imx51-ecspi";
					#address-cells = <0x01>;
					#size-cells = <0x00>;
					reg = <0x30820000 0x10000>;
					interrupts = <0x00 0x1f 0x04>;
					clocks = <0x02 0x88 0x02 0x88>;
					clock-names = "ipg\0per";
					dmas = <0x22 0x00 0x07 0x01 0x22 0x01 0x07 0x02>;
					dma-names = "rx\0tx";
					status = "disabled";
				};

				spi@30830000 {
					compatible = "fsl,imx8mn-ecspi\0fsl,imx51-ecspi";
					#address-cells = <0x01>;
					#size-cells = <0x00>;
					reg = <0x30830000 0x10000>;
					interrupts = <0x00 0x20 0x04>;
					clocks = <0x02 0x89 0x02 0x89>;
					clock-names = "ipg\0per";
					dmas = <0x22 0x02 0x07 0x01 0x22 0x03 0x07 0x02>;
					dma-names = "rx\0tx";
					status = "disabled";
				};

				spi@30840000 {
					compatible = "fsl,imx8mn-ecspi\0fsl,imx51-ecspi";
					#address-cells = <0x01>;
					#size-cells = <0x00>;
					reg = <0x30840000 0x10000>;
					interrupts = <0x00 0x21 0x04>;
					clocks = <0x02 0x8a 0x02 0x8a>;
					clock-names = "ipg\0per";
					dmas = <0x22 0x04 0x07 0x01 0x22 0x05 0x07 0x02>;
					dma-names = "rx\0tx";
					status = "disabled";
				};

				serial@30860000 {
					compatible = "fsl,imx8mn-uart\0fsl,imx6q-uart";
					reg = <0x30860000 0x10000>;
					interrupts = <0x00 0x1a 0x04>;
					clocks = <0x02 0xa9 0x02 0xa9>;
					clock-names = "ipg\0per";
					dmas = <0x22 0x16 0x04 0x00 0x22 0x17 0x04 0x00>;
					dma-names = "rx\0tx";
					status = "okay";
					pinctrl-names = "default";
					pinctrl-0 = <0x23>;
					assigned-clocks = <0x02 0x6d>;
					assigned-clock-parents = <0x02 0x31>;
					fsl,uart-has-rtscts;

					bluetooth {
						compatible = "nxp,88w8987-bt";
					};
				};

				serial@30880000 {
					compatible = "fsl,imx8mn-uart\0fsl,imx6q-uart";
					reg = <0x30880000 0x10000>;
					interrupts = <0x00 0x1c 0x04>;
					clocks = <0x02 0xab 0x02 0xab>;
					clock-names = "ipg\0per";
					dmas = <0x22 0x1a 0x04 0x00 0x22 0x1b 0x04 0x00>;
					dma-names = "rx\0tx";
					status = "okay";
					pinctrl-names = "default";
					pinctrl-0 = <0x24>;
					assigned-clocks = <0x02 0x6f>;
					assigned-clock-parents = <0x02 0x31>;
					uart-has-rtscts;
				};

				serial@30890000 {
					compatible = "fsl,imx8mn-uart\0fsl,imx6q-uart";
					reg = <0x30890000 0x10000>;
					interrupts = <0x00 0x1b 0x04>;
					clocks = <0x02 0xaa 0x02 0xaa>;
					clock-names = "ipg\0per";
					status = "okay";
					pinctrl-names = "default";
					pinctrl-0 = <0x25>;
				};
			};

			crypto@30900000 {
				compatible = "fsl,sec-v4.0";
				#address-cells = <0x01>;
				#size-cells = <0x01>;
				reg = <0x30900000 0x40000>;
				ranges = <0x00 0x30900000 0x40000>;
				interrupts = <0x00 0x5b 0x04>;
				clocks = <0x02 0x54 0x02 0x56>;
				clock-names = "aclk\0ipg";

				jr@1000 {
					compatible = "fsl,sec-v4.0-job-ring";
					reg = <0x1000 0x1000>;
					interrupts = <0x00 0x69 0x04>;
					status = "disabled";
				};

				jr@2000 {
					compatible = "fsl,sec-v4.0-job-ring";
					reg = <0x2000 0x1000>;
					interrupts = <0x00 0x6a 0x04>;
				};

				jr@3000 {
					compatible = "fsl,sec-v4.0-job-ring";
					reg = <0x3000 0x1000>;
					interrupts = <0x00 0x72 0x04>;
				};
			};

			i2c@30a20000 {
				compatible = "fsl,imx8mn-i2c\0fsl,imx21-i2c";
				#address-cells = <0x01>;
				#size-cells = <0x00>;
				reg = <0x30a20000 0x10000>;
				interrupts = <0x00 0x23 0x04>;
				clocks = <0x02 0x91>;
				status = "okay";
				clock-frequency = <0x61a80>;
				pinctrl-names = "default";
				pinctrl-0 = <0x26>;

				pmic@25 {
					compatible = "nxp,pca9450b";
					reg = <0x25>;
					pinctrl-names = "default";
					pinctrl-0 = <0x27>;
					interrupt-parent = <0x28>;
					interrupts = <0x03 0x08>;

					regulators {

						BUCK1 {
							regulator-name = "VDD_SOC_0V9";
							regulator-min-microvolt = <0xcf850>;
							regulator-max-microvolt = <0xe7ef0>;
							regulator-boot-on;
							regulator-always-on;
							regulator-ramp-delay = <0xc35>;
							phandle = <0x07>;
						};

						BUCK4 {
							regulator-name = "VDD_3V3";
							regulator-min-microvolt = <0x325aa0>;
							regulator-max-microvolt = <0x325aa0>;
							regulator-boot-on;
							regulator-always-on;
						};

						BUCK5 {
							regulator-name = "VDD_1V8";
							regulator-min-microvolt = <0x1b7740>;
							regulator-max-microvolt = <0x1b7740>;
							regulator-boot-on;
							regulator-always-on;
						};

						BUCK6 {
							regulator-name = "NVCC_DRAM_1V35";
							regulator-min-microvolt = <0x149970>;
							regulator-max-microvolt = <0x149970>;
							regulator-boot-on;
							regulator-always-on;
						};

						LDO1 {
							regulator-name = "NVCC_SNVS_1V8";
							regulator-min-microvolt = <0x1b7740>;
							regulator-max-microvolt = <0x1b7740>;
							regulator-boot-on;
							regulator-always-on;
						};

						LDO2 {
							regulator-name = "VDD_SNVS_0V8";
							regulator-min-microvolt = "\0\f5";
							regulator-max-microvolt = "\0\f5";
							regulator-boot-on;
							regulator-always-on;
						};

						LDO3 {
							regulator-name = "VDDA_1V8";
							regulator-min-microvolt = <0x1b7740>;
							regulator-max-microvolt = <0x1b7740>;
							regulator-boot-on;
							regulator-always-on;
						};

						LDO4 {
							regulator-name = "VDD_PHY_1V2";
							regulator-min-microvolt = <0x124f80>;
							regulator-max-microvolt = <0x124f80>;
							regulator-boot-on;
							regulator-always-on;
						};

						LDO5 {
							regulator-name = "NVCC_SD2";
							regulator-min-microvolt = <0x1b7740>;
							regulator-max-microvolt = <0x325aa0>;
							regulator-boot-on;
							regulator-always-on;
						};
					};
				};
			};

			i2c@30a30000 {
				compatible = "fsl,imx8mn-i2c\0fsl,imx21-i2c";
				#address-cells = <0x01>;
				#size-cells = <0x00>;
				reg = <0x30a30000 0x10000>;
				interrupts = <0x00 0x24 0x04>;
				clocks = <0x02 0x92>;
				status = "okay";
				clock-frequency = <0x61a80>;
				pinctrl-names = "default\0gpio";
				pinctrl-0 = <0x29>;
				pinctrl-1 = <0x2a>;
				scl-gpios = <0x2b 0x10 0x00>;
				sda-gpios = <0x2b 0x11 0x00>;

				tcpc@50 {
					compatible = "nxp,ptn5110";
					pinctrl-names = "default";
					pinctrl-0 = <0x2c>;
					reg = <0x50>;
					interrupt-parent = <0x2d>;
					interrupts = <0x0b 0x08>;
					status = "okay";

					port {

						endpoint {
							remote-endpoint = <0x2e>;
							phandle = <0x4e>;
						};
					};

					connector {
						compatible = "usb-c-connector";
						label = "USB-C";
						power-role = "dual";
						data-role = "dual";
						try-power-role = "sink";
						source-pdos = <0x401912c>;
						sink-pdos = <0x401912c 0x9901912c>;
						op-sink-microwatt = <0xe4e1c0>;
						self-powered;
					};
				};
			};

			i2c@30a40000 {
				#address-cells = <0x01>;
				#size-cells = <0x00>;
				compatible = "fsl,imx8mn-i2c\0fsl,imx21-i2c";
				reg = <0x30a40000 0x10000>;
				interrupts = <0x00 0x25 0x04>;
				clocks = <0x02 0x93>;
				status = "okay";
				clock-frequency = <0x186a0>;
				pinctrl-names = "default\0gpio";
				pinctrl-0 = <0x2f>;
				pinctrl-1 = <0x30>;
				scl-gpios = <0x2b 0x12 0x00>;
				sda-gpios = <0x2b 0x13 0x00>;

				gpio@20 {
					compatible = "ti,tca6416";
					reg = <0x20>;
					gpio-controller;
					#gpio-cells = <0x02>;
					phandle = <0x32>;
				};

				ak4458@10 {
					#sound-dai-cells = <0x00>;
					compatible = "asahi-kasei,ak4458";
					reg = <0x10>;
					AVDD-supply = <0x31>;
					DVDD-supply = <0x31>;
					status = "disabled";
				};

				ak4458@12 {
					#sound-dai-cells = <0x00>;
					compatible = "asahi-kasei,ak4458";
					reg = <0x12>;
					AVDD-supply = <0x31>;
					DVDD-supply = <0x31>;
					status = "disabled";
				};

				ak5558@13 {
					#sound-dai-cells = <0x00>;
					compatible = "asahi-kasei,ak5558";
					reg = <0x13>;
					reset-gpios = <0x32 0x03 0x01>;
					AVDD-supply = <0x31>;
					DVDD-supply = <0x31>;
					status = "disabled";
					phandle = <0x60>;
				};

				ak4497@11 {
					#sound-dai-cells = <0x00>;
					compatible = "asahi-kasei,ak4497";
					reg = <0x11>;
					reset-gpios = <0x32 0x05 0x01>;
					AVDD-supply = <0x31>;
					DVDD-supply = <0x31>;
					status = "disabled";
				};

				ov5640_mipi@3c {
					compatible = "ovti,ov5640";
					reg = <0x3c>;
					pinctrl-names = "default";
					pinctrl-0 = <0x33 0x34>;
					clocks = <0x02 0x7b>;
					clock-names = "xclk";
					assigned-clocks = <0x02 0x7b>;
					assigned-clock-parents = <0x02 0x02>;
					assigned-clock-rates = <0x16e3600>;
					csi_id = <0x00>;
					powerdown-gpios = <0x28 0x07 0x00>;
					reset-gpios = <0x28 0x06 0x01>;
					mclk = <0x16e3600>;
					mclk_source = <0x00>;
					mipi_csi;
					status = "okay";

					port {

						endpoint {
							remote-endpoint = <0x35>;
							data-lanes = <0x01 0x02>;
							clocks-lanes = <0x00>;
							phandle = <0x10>;
						};
					};
				};
			};

			i2c@30a50000 {
				compatible = "fsl,imx8mn-i2c\0fsl,imx21-i2c";
				#address-cells = <0x01>;
				#size-cells = <0x00>;
				reg = <0x30a50000 0x10000>;
				interrupts = <0x00 0x26 0x04>;
				clocks = <0x02 0x94>;
				status = "disabled";
			};

			serial@30a60000 {
				compatible = "fsl,imx8mn-uart\0fsl,imx6q-uart";
				reg = <0x30a60000 0x10000>;
				interrupts = <0x00 0x1d 0x04>;
				clocks = <0x02 0xac 0x02 0xac>;
				clock-names = "ipg\0per";
				dmas = <0x22 0x1c 0x04 0x00 0x22 0x1d 0x04 0x00>;
				dma-names = "rx\0tx";
				status = "disabled";
			};

			mailbox@30aa0000 {
				compatible = "fsl,imx8mn-mu\0fsl,imx6sx-mu";
				reg = <0x30aa0000 0x10000>;
				interrupts = <0x00 0x58 0x04>;
				clocks = <0x02 0x95>;
				#mbox-cells = <0x02>;
			};

			mmc@30b40000 {
				compatible = "fsl,imx8mn-usdhc\0fsl,imx8mm-usdhc\0fsl,imx7d-usdhc";
				reg = <0x30b40000 0x10000>;
				interrupts = <0x00 0x16 0x04>;
				clocks = <0x02 0x56 0x02 0x4d 0x02 0xae>;
				clock-names = "ipg\0ahb\0per";
				fsl,tuning-start-tap = <0x14>;
				fsl,tuning-step = <0x02>;
				bus-width = <0x04>;
				status = "okay";
				#address-cells = <0x01>;
				#size-cells = <0x00>;
				pinctrl-names = "default\0state_100mhz\0state_200mhz";
				pinctrl-0 = <0x36 0x37>;
				pinctrl-1 = <0x38 0x37>;
				pinctrl-2 = <0x39 0x37>;
				keep-power-in-suspend;
				non-removable;
				wakeup-source;
				fsl,sdio-async-interrupt-enabled;
				vmmc-supply = <0x3a>;

				wifi_wake_host {
					compatible = "nxp,wifi-wake-host";
					interrupt-parent = <0x2d>;
					interrupts = <0x09 0x08>;
					interrupt-names = "host-wake";
				};
			};

			mmc@30b50000 {
				compatible = "fsl,imx8mn-usdhc\0fsl,imx8mm-usdhc\0fsl,imx7d-usdhc";
				reg = <0x30b50000 0x10000>;
				interrupts = <0x00 0x17 0x04>;
				clocks = <0x02 0x56 0x02 0x4d 0x02 0xaf>;
				clock-names = "ipg\0ahb\0per";
				fsl,tuning-start-tap = <0x14>;
				fsl,tuning-step = <0x02>;
				bus-width = <0x04>;
				status = "okay";
				assigned-clocks = <0x02 0x68>;
				assigned-clock-rates = <0xbebc200>;
				pinctrl-names = "default\0state_100mhz\0state_200mhz";
				pinctrl-0 = <0x3b 0x3c>;
				pinctrl-1 = <0x3d 0x3c>;
				pinctrl-2 = <0x3e 0x3c>;
				cd-gpios = <0x28 0x0f 0x01>;
				vmmc-supply = <0x3f>;
			};

			mmc@30b60000 {
				compatible = "fsl,imx8mn-usdhc\0fsl,imx8mm-usdhc\0fsl,imx7d-usdhc";
				reg = <0x30b60000 0x10000>;
				interrupts = <0x00 0x18 0x04>;
				clocks = <0x02 0x56 0x02 0x4d 0x02 0xbc>;
				clock-names = "ipg\0ahb\0per";
				fsl,tuning-start-tap = <0x14>;
				fsl,tuning-step = <0x02>;
				bus-width = <0x08>;
				status = "okay";
				assigned-clocks = <0x02 0xbc>;
				assigned-clock-rates = <0x17d78400>;
				pinctrl-names = "default\0state_100mhz\0state_200mhz";
				pinctrl-0 = <0x40>;
				pinctrl-1 = <0x41>;
				pinctrl-2 = <0x42>;
				non-removable;
			};

			spi@30bb0000 {
				#address-cells = <0x01>;
				#size-cells = <0x00>;
				compatible = "nxp,imx8mm-fspi";
				reg = <0x30bb0000 0x10000 0x8000000 0x10000000>;
				reg-names = "fspi_base\0fspi_mmap";
				interrupts = <0x00 0x6b 0x04>;
				clocks = <0x02 0x9b 0x02 0x9b>;
				clock-names = "fspi_en\0fspi";
				status = "okay";
				pinctrl-names = "default";
				pinctrl-0 = <0x43>;

				flash@0 {
					compatible = "jedec,spi-nor";
					reg = <0x00>;
					#address-cells = <0x01>;
					#size-cells = <0x01>;
					spi-max-frequency = <0x9e4f580>;
					spi-tx-bus-width = <0x01>;
					spi-rx-bus-width = <0x04>;
				};
			};

			dma-controller@30bd0000 {
				compatible = "fsl,imx8mn-sdma\0fsl,imx8mq-sdma\0fsl,imx7d-sdma";
				reg = <0x30bd0000 0x10000>;
				interrupts = <0x00 0x02 0x04>;
				clocks = <0x02 0xa7 0x02 0x54>;
				clock-names = "ipg\0ahb";
				#dma-cells = <0x03>;
				fsl,sdma-ram-script-name = "imx/sdma/sdma-imx7d.bin";
				phandle = <0x22>;
			};

			ethernet@30be0000 {
				compatible = "fsl,imx8mn-fec\0fsl,imx8mq-fec\0fsl,imx6sx-fec";
				reg = <0x30be0000 0x10000>;
				interrupts = <0x00 0x76 0x04 0x00 0x77 0x04 0x00 0x78 0x04 0x00 0x79 0x04>;
				clocks = <0x02 0x8b 0x02 0x8b 0x02 0x63 0x02 0x62 0x02 0x64>;
				clock-names = "ipg\0ahb\0ptp\0enet_clk_ref\0enet_out";
				assigned-clocks = <0x02 0x4c 0x02 0x63 0x02 0x62 0x02 0x64>;
				assigned-clock-parents = <0x02 0x36 0x02 0x3a 0x02 0x3b 0x02 0x39>;
				assigned-clock-rates = <0x00 0x5f5e100 0x7735940 0x00>;
				fsl,num-tx-queues = <0x03>;
				fsl,num-rx-queues = <0x03>;
				nvmem-cells = <0x44>;
				nvmem-cell-names = "mac-address";
				fsl,stop-mode = <0x45 0x10 0x03>;
				status = "okay";
				pinctrl-names = "default";
				pinctrl-0 = <0x46>;
				phy-mode = "rgmii-id";
				phy-handle = <0x47>;
				fsl,magic-packet;

				mdio {
					#address-cells = <0x01>;
					#size-cells = <0x00>;

					ethernet-phy@0 {
						compatible = "ethernet-phy-ieee802.3-c22";
						reg = <0x00>;
						reset-gpios = <0x48 0x16 0x01>;
						reset-assert-us = <0x2710>;
						reset-deassert-us = <0x13880>;
						realtek,aldps-enable;
						realtek,clkout-disable;
						qca,disable-smarteee;
						vddio-supply = <0x49>;
						phandle = <0x47>;

						vddio-regulator {
							regulator-min-microvolt = <0x1b7740>;
							regulator-max-microvolt = <0x1b7740>;
							phandle = <0x49>;
						};
					};
				};
			};
		};

		bus@32c00000 {
			compatible = "fsl,aips-bus\0simple-bus";
			reg = <0x32c00000 0x400000>;
			#address-cells = <0x01>;
			#size-cells = <0x01>;
			ranges;

			blk-ctrl@32e28000 {
				compatible = "fsl,imx8mn-disp-blk-ctrl\0syscon";
				reg = <0x32e28000 0x100>;
				power-domains = <0x21 0x21 0x21 0x4a 0x4a>;
				power-domain-names = "bus\0isi\0lcdif\0mipi-dsi\0mipi-csi";
				clocks = <0x02 0x4e 0x02 0x4f 0x02 0xb8 0x02 0xb9 0x02 0xb8 0x02 0xb9 0x02 0xba 0x02 0x7d 0x02 0x7e 0x02 0x82 0x02 0xbb>;
				clock-names = "disp_axi\0disp_apb\0disp_axi_root\0disp_apb_root\0lcdif-axi\0lcdif-apb\0lcdif-pix\0dsi-pclk\0dsi-ref\0csi-aclk\0csi-pclk";
				#power-domain-cells = <0x01>;
				phandle = <0x0e>;
			};

			usb@32e40000 {
				compatible = "fsl,imx8mn-usb\0fsl,imx7d-usb";
				reg = <0x32e40000 0x200>;
				interrupts = <0x00 0x28 0x04>;
				clocks = <0x02 0xad>;
				clock-names = "usb1_ctrl_root_clk";
				assigned-clocks = <0x02 0x50>;
				assigned-clock-parents = <0x02 0x40>;
				phys = <0x4b>;
				fsl,usbmisc = <0x4c 0x00>;
				power-domains = <0x4d>;
				status = "okay";
				dr_mode = "otg";
				hnp-disable;
				srp-disable;
				adp-disable;
				usb-role-switch;
				disable-over-current;
				samsung,picophy-pre-emp-curr-control = <0x03>;
				samsung,picophy-dc-vol-level-adjust = <0x07>;

				port {

					endpoint {
						remote-endpoint = <0x4e>;
						phandle = <0x2e>;
					};
				};
			};

			usbmisc@32e40200 {
				compatible = "fsl,imx8mn-usbmisc\0fsl,imx7d-usbmisc";
				#index-cells = <0x01>;
				reg = <0x32e40200 0x200>;
				phandle = <0x4c>;
			};
		};

		dma-controller@33000000 {
			compatible = "fsl,imx7d-dma-apbh\0fsl,imx28-dma-apbh";
			reg = <0x33000000 0x2000>;
			interrupts = <0x00 0x0c 0x04 0x00 0x0c 0x04 0x00 0x0c 0x04 0x00 0x0c 0x04>;
			interrupt-names = "gpmi0\0gpmi1\0gpmi2\0gpmi3";
			#dma-cells = <0x01>;
			dma-channels = <0x04>;
			clocks = <0x02 0xc0>;
			phandle = <0x4f>;
		};

		nand-controller@33002000 {
			compatible = "fsl,imx8mn-gpmi-nand\0fsl,imx7d-gpmi-nand";
			#address-cells = <0x01>;
			#size-cells = <0x00>;
			reg = <0x33002000 0x2000 0x33004000 0x4000>;
			reg-names = "gpmi-nand\0bch";
			interrupts = <0x00 0x0e 0x04>;
			interrupt-names = "bch";
			clocks = <0x02 0x9c 0x02 0xc0>;
			clock-names = "gpmi_io\0gpmi_bch_apb";
			dmas = <0x4f 0x00>;
			dma-names = "rx-tx";
			status = "disabled";
		};

		interrupt-controller@38800000 {
			compatible = "arm,gic-v3";
			reg = <0x38800000 0x10000 0x38880000 0xc0000>;
			#interrupt-cells = <0x03>;
			interrupt-controller;
			interrupts = <0x01 0x09 0x04>;
			phandle = <0x01>;
		};

		ddr-pmu@3d800000 {
			compatible = "fsl,imx8mn-ddr-pmu\0fsl,imx8m-ddr-pmu";
			reg = <0x3d800000 0x400000>;
			interrupts = <0x00 0x62 0x04>;
		};
	};

	usbphynop1 {
		#phy-cells = <0x00>;
		compatible = "usb-nop-xceiv";
		clocks = <0x02 0x72>;
		assigned-clocks = <0x02 0x72>;
		assigned-clock-parents = <0x02 0x32>;
		clock-names = "main_clk";
		power-domains = <0x50>;
		wakeup-source;
		phandle = <0x4b>;
	};

	chosen {
		stdout-path = "/soc@0/bus@30800000/spba-bus@30800000/serial@30890000";
	};

	gpio-leds {
		compatible = "gpio-leds";
		pinctrl-names = "default";
		pinctrl-0 = <0x51>;

		status {
			label = "yellow:status";
			gpios = <0x52 0x10 0x00>;
			default-state = "on";
		};
	};

	memory@40000000 {
		device_type = "memory";
		reg = <0x00 0x40000000 0x00 0x80000000>;
	};

	ir-receiver {
		compatible = "gpio-ir-receiver";
		gpios = <0x28 0x0d 0x01>;
		pinctrl-names = "default";
		pinctrl-0 = <0x53>;
		linux,autosuspend-period = <0x7d>;
	};

	regulator-usdhc1 {
		compatible = "regulator-fixed";
		regulator-name = "WLAN_EN";
		pinctrl-names = "default";
		pinctrl-0 = <0x54>;
		regulator-min-microvolt = <0x325aa0>;
		regulator-max-microvolt = <0x325aa0>;
		gpio = <0x2d 0x0a 0x00>;
		enable-active-high;
		phandle = <0x3a>;
	};

	regulator-usdhc2 {
		compatible = "regulator-fixed";
		pinctrl-names = "default";
		pinctrl-0 = <0x55>;
		regulator-name = "VSD_3V3";
		regulator-min-microvolt = <0x325aa0>;
		regulator-max-microvolt = <0x325aa0>;
		gpio = <0x2d 0x13 0x00>;
		off-on-delay-us = <0x2ee0>;
		enable-active-high;
		phandle = <0x3f>;
	};

	regulator-audio-board {
		compatible = "regulator-fixed";
		regulator-name = "EXT_PWREN";
		regulator-min-microvolt = <0x325aa0>;
		regulator-max-microvolt = <0x325aa0>;
		enable-active-high;
		startup-delay-us = <0x493e0>;
		gpio = <0x32 0x01 0x00>;
		regulator-always-on;
		phandle = <0x31>;
	};

	audio-codec-bt-sco {
		compatible = "linux,bt-sco";
		#sound-dai-cells = <0x01>;
		phandle = <0x59>;
	};

	audio-codec {
		#sound-dai-cells = <0x00>;
		compatible = "wlf,wm8524";
		pinctrl-names = "default";
		pinctrl-0 = <0x56>;
		wlf,mute-gpios = <0x2b 0x15 0x01>;
		clocks = <0x02 0x9f>;
		clock-names = "mclk";
		phandle = <0x5b>;
	};

	sound-bt-sco {
		compatible = "simple-audio-card";
		simple-audio-card,name = "bt-sco-audio";
		simple-audio-card,format = "dsp_a";
		simple-audio-card,bitclock-inversion;
		simple-audio-card,frame-master = <0x57>;
		simple-audio-card,bitclock-master = <0x57>;

		simple-audio-card,cpu {
			sound-dai = <0x58>;
			dai-tdm-slot-num = <0x02>;
			dai-tdm-slot-width = <0x10>;
			phandle = <0x57>;
		};

		simple-audio-card,codec {
			sound-dai = <0x59 0x01>;
		};
	};

	sound-wm8524 {
		compatible = "fsl,imx-audio-wm8524";
		model = "wm8524-audio";
		audio-cpu = <0x5a>;
		audio-codec = <0x5b>;
		audio-asrc = <0x5c>;
		audio-routing = "Line Out Jack\0LINEVOUTL\0Line Out Jack\0LINEVOUTR";
	};

	sound-micfil {
		compatible = "fsl,imx-audio-card";
		model = "micfil-audio";

		pri-dai-link {
			link-name = "micfil hifi";
			format = "i2s";

			cpu {
				sound-dai = <0x5d>;
			};
		};
	};

	sound-spdif {
		compatible = "fsl,imx-audio-spdif";
		model = "imx-spdif";
		spdif-controller = <0x5e>;
		spdif-out;
		spdif-in;
	};

	sound-ak5558 {
		compatible = "fsl,imx-audio-card";
		model = "ak5558-audio";
		status = "disabled";

		pri-dai-link {
			link-name = "akcodec";
			format = "i2s";
			fsl,mclk-equal-bclk;

			cpu {
				sound-dai = <0x5f>;
			};

			codec {
				sound-dai = <0x60>;
			};
		};

		fe-dai-link {
			link-name = "HiFi-ASRC-FE";
			format = "i2s";

			cpu {
				sound-dai = <0x5c>;
			};
		};

		be-dai-link {
			link-name = "HiFi-ASRC-BE";
			format = "dsp_b";
			dai-tdm-slot-num = <0x08>;
			dai-tdm-slot-width = <0x20>;

			cpu {
				sound-dai = <0x5f>;
			};

			codec {
				sound-dai = <0x60>;
			};
		};
	};
};
